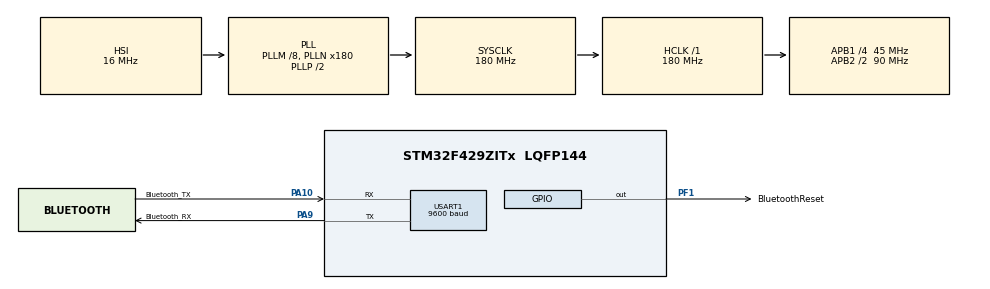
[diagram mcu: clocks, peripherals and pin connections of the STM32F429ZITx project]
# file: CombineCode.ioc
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Mcu.Family=STM32F4
RCC.CortexFreq_Value=180000000
RTC.Alarm=RTC_ALARM_A
PA10.Mode=Asynchronous
NVIC.TIM6_DAC_IRQn=true\:0\:0\:false\:false\:true\:true\:true
USART1.BaudRate=9600
PA9.GPIO_Label=Bluetooth_RX
RTC.AlarmMaskDateWeekDay=RTC_ALARMMASK_DATEWEEKDAY
TIM6.Prescaler=720
VP_TIM6_VS_ClockSourceINT.Mode=Enable_Timer
VP_RTC_VS_RTC_Activate.Mode=RTC_Enabled
PC14/OSC32_IN.Mode=LSE-External-Oscillator
RCC.APB1CLKDivider=RCC_HCLK_DIV4
VP_RTC_VS_RTC_Alarm_A_Intern.Mode=Alarm A
RCC.SYSCLKSource=RCC_SYSCLKSOURCE_PLLCLK
ProjectManager.StackSize=0x400
PA13.Signal=SYS_JTMS-SWDIO
PA9.Mode=Asynchronous
ProjectManager.TargetToolchain=STM32CubeIDE
PH0/OSC_IN.Mode=HSE-External-Oscillator
RCC.HCLKFreq_Value=180000000
RCC.APB2TimFreq_Value=180000000
PA9.Signal=USART1_TX
PH1/OSC_OUT.Signal=RCC_OSC_OUT
RTC.Format=RTC_FORMAT_BIN
RCC.AHBFreq_Value=180000000
RCC.HSE_VALUE=25000000
RTC.Minutes=59
board=custom
PF1.GPIO_Label=BluetoothReset
RCC.VCOOutputFreq_Value=360000000
PH0/OSC_IN.Signal=RCC_OSC_IN
RCC.APB2Freq_Value=90000000
PA14.Mode=Serial_Wire
PA10.GPIO_Label=Bluetooth_TX
TIM6.Period=1999
PF1.Signal=GPIO_Output
PA13.Mode=Serial_Wire
NVIC.RTC_Alarm_IRQn=true\:0\:0\:false\:false\:true\:true\:true
PH1/OSC_OUT.Mode=HSE-External-Oscillator
Mcu.Name=STM32F429ZITx
RTC.AlarmDateWeekDaySel=RTC_ALARMDATEWEEKDAYSEL_WEEKDAY
RCC.48MHZClocksFreq_Value=90000000
RCC.SYSCLKFreq_VALUE=180000000
RTC.Hours=23
Mcu.Package=LQFP144
PC14/OSC32_IN.Signal=RCC_OSC32_IN
PC15/OSC32_OUT.Mode=LSE-External-Oscillator
USART1.VirtualMode=VM_ASYNC
PA10.Signal=USART1_RX
PA14.Signal=SYS_JTCK-SWCLK
VP_RTC_VS_RTC_Calendar.Mode=RTC_Calendar
ProjectManager.HeapSize=0x200
RCC.HSI_VALUE=16000000
NVIC.PriorityGroup=NVIC_PRIORITYGROUP_4
RCC.APB2CLKDivider=RCC_HCLK_DIV2
RCC.PLLM=8
RCC.PLLN=180
RCC.APB1TimFreq_Value=90000000
PC15/OSC32_OUT.Signal=RCC_OSC32_OUT
NVIC.USART1_IRQn=true\:0\:0\:false\:false\:true\:true\:true
RTC.Seconds=59
RCC.APB1Freq_Value=45000000

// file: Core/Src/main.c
/* USER CODE BEGIN Header */
/**
  ******************************************************************************
  * @file           : main.c
  * @brief          : Main program body
  ******************************************************************************
  * @attention
  *
  * <h2><center>&copy; Copyright (c) 2021 STMicroelectronics.
  * All rights reserved.</center></h2>
  *
  * This software component is licensed by ST under BSD 3-Clause license,
  * the "License"; You may not use this file except in compliance with the
  * License. You may obtain a copy of the License at:
  *                        opensource.org/licenses/BSD-3-Clause
  *
  ******************************************************************************
  */
/* USER CODE END Header */
#include "main.h"
#include "mylibrary.h"
#include "stm32f4xx_it.h"

#include "ltdc.h"
#include "spi.h"
#include "lcd.h"
#include "graphic.h"
#include "screens.h"

#include <stdio.h>
#include <stdlib.h>
#include <string.h>

RTC_HandleTypeDef hrtc;

TIM_HandleTypeDef htim6;

UART_HandleTypeDef huart1;

RTC_DateTypeDef gDate;
RTC_TimeTypeDef gTime;

void SystemClock_Config(void);
static void MX_GPIO_Init(void);
static void MX_TIM6_Init(void);
static void MX_USART1_UART_Init(void);
static void MX_RTC_Init(void);

void initializeGPIONVIC(void);
/* USER CODE BEGIN PFP */
char time[10], date[10];
char hr[3], min[3], sec[3];
int view_index = 0;

extern uint8_t *GRAM;
/* USER CODE END PFP */

int main(void)
{

  /* MCU Configuration--------------------------------------------------------*/

  /* Reset of all peripherals, Initializes the Flash interface and the Systick. */
  HAL_Init();

  /* Configure the system clock */
  SystemClock_Config();

  /* Initialize all configured peripherals */
  MX_GPIO_Init();

  LCD_GpioInit();
  LCD_LtdcInit();
  LCD_DispInit_Spi();
  LCD_DispInit_Ltdc();
  //initializeGPIONVIC();
  //InitialScreen();
  //MenuScreen();

  MX_TIM6_Init();
  MX_USART1_UART_Init();
  MX_RTC_Init();
  /* USER CODE BEGIN 2 */
  HAL_Delay(200);
  HAL_GPIO_WritePin(BluetoothReset_GPIO_Port, BluetoothReset_Pin, SET);
  HAL_Delay(1000);
  memset(buffer, 0, sizeof(buffer));
  HAL_TIM_Base_Start_IT(&htim6);
  __HAL_UART_ENABLE_IT(&huart1, UART_IT_RXNE);
  /* USER CODE END 2 */

  /* Infinite loop */
  while (1)
  {

	  /*
	  get_time();

	  HAL_UART_Transmit(&huart1, (uint8_t*)time, strlen(time), 500);
	  HAL_UART_Transmit(&huart1, (uint8_t*)"\n", strlen("\n"), 500);
	  HAL_Delay(1000);

	*/
	  /*
	if(buffer[buffer_index-1] == '\n'){
			  set_alarm(mtime, mdate, apm);
	}

  }
}

/**
 *
  * @brief get the rtc time and date and format both in strings
  */
void get_time(void)
{
	 RTC_DateTypeDef gDate;
	 RTC_TimeTypeDef gTime;
	/* Get the RTC current Time */
	 HAL_RTC_GetTime(&hrtc, &gTime, RTC_FORMAT_BIN);
	/* Get the RTC current Date */
	 HAL_RTC_GetDate(&hrtc, &gDate, RTC_FORMAT_BIN);
	/* Display time Format: hh:mm:ss */
	 sprintf((char*)time,"%02d:%02d:%02d",gTime.Hours, gTime.Minutes, gTime.Seconds);
	/* Display date Format: dd-mm-yy */
	 sprintf((char*)date,"%02d-%02d-%2d",gDate.Date, gDate.Month, 2000 + gDate.Year);
}

uint8_t check_time(void)
{
	char clock[5];

	/* Get the RTC current Time */
	 HAL_RTC_GetTime(&hrtc, &gTime, RTC_FORMAT_BIN);
	/* Get the RTC current Date */
	 HAL_RTC_GetDate(&hrtc, &gDate, RTC_FORMAT_BIN);

	 sprintf((char*)clock,"%02d:%02d:%02d",gTime.Hours, gTime.Minutes);
	 if(clock == mtime)
		 	 	 return 1;
	 else return 0;

	 // didn't check the weekday yet
}

void set_alarm(char timearr[], char weekday[], int apm)
{
	  RTC_AlarmTypeDef sAlarm = {0};
	  /** Enable the Alarm A
	  */
	  if(timearr[1]==':')
	  {
	  strncpy ( hr, timearr, 1 );
	  strncpy ( min, timearr+2, 2 );
	  }else{
		  strncpy ( hr, timearr, 2 );
		  strncpy ( min, timearr+3, 2 );
	  }

	  if(apm == 1)
	  {
		  sAlarm.AlarmTime.Hours = atoi(hr)+12;
	  }else{
		  sAlarm.AlarmTime.Hours = atoi(hr);
	  }
	  sAlarm.AlarmTime.Minutes = atoi(min);
	  sAlarm.AlarmTime.Seconds = 0;
	  sAlarm.AlarmTime.SubSeconds = 0;
	  sAlarm.AlarmTime.DayLightSaving = RTC_DAYLIGHTSAVING_NONE;
	  sAlarm.AlarmTime.StoreOperation = RTC_STOREOPERATION_RESET;
	  sAlarm.AlarmMask = RTC_ALARMMASK_NONE;
	  sAlarm.AlarmSubSecondMask = RTC_ALARMSUBSECONDMASK_ALL;
	  sAlarm.AlarmDateWeekDaySel = RTC_ALARMDATEWEEKDAYSEL_WEEKDAY;

	  if(strcmp(weekday, 'mon') == 0)
	  {
		  sAlarm.AlarmDateWeekDay = RTC_WEEKDAY_MONDAY;
	  }else
		  if(strcmp(weekday, "tue") == 0)
		{
			  sAlarm.AlarmDateWeekDay = RTC_WEEKDAY_TUESDAY;
		}else
			if(strcmp(weekday, "wed") == 0)
			{
				sAlarm.AlarmDateWeekDay = RTC_WEEKDAY_WEDNESDAY;
			}else
				if(strcmp(weekday,"thu") == 0)
				{
					sAlarm.AlarmDateWeekDay = RTC_WEEKDAY_THURSDAY;
				}else
					if(strcmp(weekday, "fri") == 0)
					{
						sAlarm.AlarmDateWeekDay = RTC_WEEKDAY_FRIDAY;
					}else
						  if(strcmp(weekday, "sat") == 0)
						  {
							  sAlarm.AlarmDateWeekDay = RTC_WEEKDAY_SATURDAY;
						  }else
							  if(strcmp(weekday, "sun") == 0)
							  {
								  sAlarm.AlarmDateWeekDay = RTC_WEEKDAY_SUNDAY;
							  }

	  sAlarm.Alarm = RTC_ALARM_A;
	  if (HAL_RTC_SetAlarm_IT(&hrtc, &sAlarm, RTC_FORMAT_BIN) != HAL_OK)
	  {
	    Error_Handler();
	  }
}

void set_time(char arr)
{
	  RTC_TimeTypeDef sTime = {0};
	  RTC_DateTypeDef sDate = {0};

	  strncpy ( hr, arr, 2 );
	  hr[2] = '\0';
	  strncpy ( min, arr+2, 2 );
	  min[2] = '\0';

	  sTime.Hours = atoi(hr);
	  sTime.Minutes = atoi(min);
	  sTime.Seconds = 0;
	  sTime.DayLightSaving = RTC_DAYLIGHTSAVING_NONE;
	  sTime.StoreOperation = RTC_STOREOPERATION_RESET;
	  if (HAL_RTC_SetTime(&hrtc, &sTime, RTC_FORMAT_BIN) != HAL_OK)
	  {
	    Error_Handler();
	  }
	  sDate.WeekDay = RTC_WEEKDAY_MONDAY;
	  sDate.Month = RTC_MONTH_JANUARY;
	  sDate.Date = 1;
	  sDate.Year = 0;

	  if (HAL_RTC_SetDate(&hrtc, &sDate, RTC_FORMAT_BIN) != HAL_OK)
	  {
	    Error_Handler();
	  }
}
void SystemClock_Config(void)
{
  RCC_OscInitTypeDef RCC_OscInitStruct = {0};
  RCC_ClkInitTypeDef RCC_ClkInitStruct = {0};
  RCC_PeriphCLKInitTypeDef PeriphClkInitStruct = {0};

  /** Configure the main internal regulator output voltage
  */
  __HAL_RCC_PWR_CLK_ENABLE();
  __HAL_PWR_VOLTAGESCALING_CONFIG(PWR_REGULATOR_VOLTAGE_SCALE1);
  /** Initializes the RCC Oscillators according to the specified parameters
  * in the RCC_OscInitTypeDef structure.
  */
  RCC_OscInitStruct.OscillatorType = RCC_OSCILLATORTYPE_HSI|RCC_OSCILLATORTYPE_LSI;
  RCC_OscInitStruct.HSIState = RCC_HSI_ON;
  RCC_OscInitStruct.HSICalibrationValue = RCC_HSICALIBRATION_DEFAULT;
  RCC_OscInitStruct.LSIState = RCC_LSI_ON;
  RCC_OscInitStruct.PLL.PLLState = RCC_PLL_ON;
  RCC_OscInitStruct.PLL.PLLSource = RCC_PLLSOURCE_HSI;
  RCC_OscInitStruct.PLL.PLLM = 8;
  RCC_OscInitStruct.PLL.PLLN = 180;
  RCC_OscInitStruct.PLL.PLLP = RCC_PLLP_DIV2;
  RCC_OscInitStruct.PLL.PLLQ = 4;
  if (HAL_RCC_OscConfig(&RCC_OscInitStruct) != HAL_OK)
  {
    Error_Handler();
  }
  /** Activate the Over-Drive mode
  */
  if (HAL_PWREx_EnableOverDrive() != HAL_OK)
  {
    Error_Handler();
  }
  /** Initializes the CPU, AHB and APB buses clocks
  */
  RCC_ClkInitStruct.ClockType = RCC_CLOCKTYPE_HCLK|RCC_CLOCKTYPE_SYSCLK
                              |RCC_CLOCKTYPE_PCLK1|RCC_CLOCKTYPE_PCLK2;
  RCC_ClkInitStruct.SYSCLKSource = RCC_SYSCLKSOURCE_PLLCLK;
  RCC_ClkInitStruct.AHBCLKDivider = RCC_SYSCLK_DIV1;
  RCC_ClkInitStruct.APB1CLKDivider = RCC_HCLK_DIV4;
  RCC_ClkInitStruct.APB2CLKDivider = RCC_HCLK_DIV2;

  if (HAL_RCC_ClockConfig(&RCC_ClkInitStruct, FLASH_LATENCY_5) != HAL_OK)
  {
    Error_Handler();
  }
  PeriphClkInitStruct.PeriphClockSelection = RCC_PERIPHCLK_RTC;
  PeriphClkInitStruct.RTCClockSelection = RCC_RTCCLKSOURCE_LSI;
  if (HAL_RCCEx_PeriphCLKConfig(&PeriphClkInitStruct) != HAL_OK)
  {
    Error_Handler();
  }
}

static void MX_RTC_Init(void)
{

  /** Initialize RTC Only
  */
  hrtc.Instance = RTC;
  hrtc.Init.HourFormat = RTC_HOURFORMAT_24;
  hrtc.Init.AsynchPrediv = 127;
  hrtc.Init.SynchPrediv = 255;
  hrtc.Init.OutPut = RTC_OUTPUT_DISABLE;
  hrtc.Init.OutPutPolarity = RTC_OUTPUT_POLARITY_HIGH;
  hrtc.Init.OutPutType = RTC_OUTPUT_TYPE_OPENDRAIN;
  if (HAL_RTC_Init(&hrtc) != HAL_OK)
  {
    Error_Handler();
  }

  /** Initialize RTC and set the Time and Date
  */

}

static void MX_TIM6_Init(void)
{

  TIM_MasterConfigTypeDef sMasterConfig = {0};

  htim6.Instance = TIM6;
  htim6.Init.Prescaler = 720;
  htim6.Init.CounterMode = TIM_COUNTERMODE_UP;
  htim6.Init.Period = 1999;
  htim6.Init.AutoReloadPreload = TIM_AUTORELOAD_PRELOAD_DISABLE;
  if (HAL_TIM_Base_Init(&htim6) != HAL_OK)
  {
    Error_Handler();
  }
  sMasterConfig.MasterOutputTrigger = TIM_TRGO_RESET;
  sMasterConfig.MasterSlaveMode = TIM_MASTERSLAVEMODE_DISABLE;
  if (HAL_TIMEx_MasterConfigSynchronization(&htim6, &sMasterConfig) != HAL_OK)
  {
    Error_Handler();
  }

}

static void MX_USART1_UART_Init(void)
{

  huart1.Instance = USART1;
  huart1.Init.BaudRate = 9600;
  huart1.Init.WordLength = UART_WORDLENGTH_8B;
  huart1.Init.StopBits = UART_STOPBITS_1;
  huart1.Init.Parity = UART_PARITY_NONE;
  huart1.Init.Mode = UART_MODE_TX_RX;
  huart1.Init.HwFlowCtl = UART_HWCONTROL_NONE;
  huart1.Init.OverSampling = UART_OVERSAMPLING_16;
  if (HAL_UART_Init(&huart1) != HAL_OK)
  {
    Error_Handler();
  }

}

static void MX_GPIO_Init(void)
{
  GPIO_InitTypeDef GPIO_InitStruct = {0};

  /* GPIO Ports Clock Enable */
  __HAL_RCC_GPIOC_CLK_ENABLE();
  __HAL_RCC_GPIOF_CLK_ENABLE();
  __HAL_RCC_GPIOH_CLK_ENABLE();
  __HAL_RCC_GPIOA_CLK_ENABLE();

  /*Configure GPIO pin Output Level */
  HAL_GPIO_WritePin(BluetoothReset_GPIO_Port, BluetoothReset_Pin, GPIO_PIN_RESET);

  /*Configure GPIO pin : BluetoothReset_Pin */
  GPIO_InitStruct.Pin = BluetoothReset_Pin;
  GPIO_InitStruct.Mode = GPIO_MODE_OUTPUT_PP;
  GPIO_InitStruct.Pull = GPIO_NOPULL;
  GPIO_InitStruct.Speed = GPIO_SPEED_FREQ_LOW;
  HAL_GPIO_Init(BluetoothReset_GPIO_Port, &GPIO_InitStruct);

}

void Error_Handler(void)
{
  __disable_irq();
  while (1)
  {
  }
}

void initializeGPIONVIC(void)
{
	/*Configure GPIO pin: PA0 */
	GPIO_InitTypeDef GPIO_InitStruct = {0};
	GPIO_InitStruct.Pin = GPIO_PIN_0;
	GPIO_InitStruct.Mode = GPIO_MODE_IT_RISING;
	GPIO_InitStruct.Pull = GPIO_NOPULL;
	HAL_GPIO_Init(GPIOA, &GPIO_InitStruct);
	/*EXTI interrupt init */
	HAL_NVIC_SetPriority(EXTI0_IRQn, 3, 0);
	HAL_NVIC_EnableIRQ(EXTI0_IRQn);

	/*Configure GPIO pin: PE1 */
	GPIO_InitStruct.Pin = GPIO_PIN_1;
	GPIO_InitStruct.Mode = GPIO_MODE_IT_RISING;
	GPIO_InitStruct.Pull = GPIO_NOPULL;
	HAL_GPIO_Init(GPIOE, &GPIO_InitStruct);
	/*EXTI interrupt init */
	HAL_NVIC_SetPriority(EXTI1_IRQn, 3, 0);
	HAL_NVIC_EnableIRQ(EXTI1_IRQn);

	/*Configure GPIO pin: PE2 */
	GPIO_InitStruct.Pin = GPIO_PIN_2;
	GPIO_InitStruct.Mode = GPIO_MODE_IT_RISING;
	GPIO_InitStruct.Pull = GPIO_NOPULL;
	HAL_GPIO_Init(GPIOE, &GPIO_InitStruct);
	/*EXTI interrupt init */
	HAL_NVIC_SetPriority(EXTI2_IRQn, 3, 0);
	HAL_NVIC_EnableIRQ(EXTI2_IRQn);

	/*Configure GPIO pin: PE3 */
	GPIO_InitStruct.Pin = GPIO_PIN_3;
	GPIO_InitStruct.Mode = GPIO_MODE_IT_RISING;
	GPIO_InitStruct.Pull = GPIO_NOPULL;
	HAL_GPIO_Init(GPIOE, &GPIO_InitStruct);
	/*EXTI interrupt init */
	HAL_NVIC_SetPriority(EXTI3_IRQn, 3, 0);
	HAL_NVIC_EnableIRQ(EXTI3_IRQn);

	/*Configure GPIO pin: PE4 */
	GPIO_InitStruct.Pin = GPIO_PIN_4;
	GPIO_InitStruct.Mode = GPIO_MODE_IT_RISING;
	GPIO_InitStruct.Pull = GPIO_NOPULL;
	HAL_GPIO_Init(GPIOE, &GPIO_InitStruct);
	/*EXTI interrupt init */
	HAL_NVIC_SetPriority(EXTI4_IRQn, 3, 0);
	HAL_NVIC_EnableIRQ(EXTI4_IRQn);
}

// EXIT0 handler
void EXTI0_IRQHandler(void)
{
	if (view_index == 0)
	{
		BluetoothScreen();
	}
	else if (view_index == 1)
	{
		ScheduleScreen();
	}
	else if (view_index == 2)
	{
		DispensedScreen();
	}
	else if (view_index == 3)
	{
		MenuScreen();
	}
	view_index = (view_index + 1) % 4;
	HAL_GPIO_EXTI_IRQHandler(GPIO_PIN_0);
}

void EXTI1_IRQHandler(void)
{
	MenuScreen();
	HAL_GPIO_EXTI_IRQHandler(GPIO_PIN_1);
}

void EXTI2_IRQHandler(void)
{
	BluetoothScreen();
	HAL_GPIO_EXTI_IRQHandler(GPIO_PIN_2);
}

void EXTI3_IRQHandler(void)
{
	ScheduleScreen();
	HAL_GPIO_EXTI_IRQHandler(GPIO_PIN_3);
}

void EXTI4_IRQHandler(void)
{
	DispensedScreen();
	HAL_GPIO_EXTI_IRQHandler(GPIO_PIN_4);
}

/************************ (C) COPYRIGHT STMicroelectronics *****END OF FILE****/
